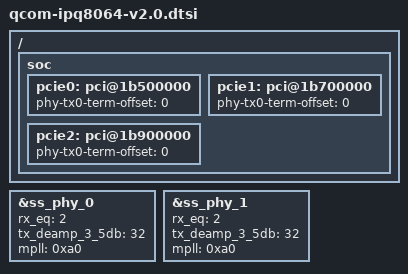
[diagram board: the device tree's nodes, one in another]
#include "qcom-ipq8064-v1.0.dtsi"

/ {
	soc: soc {

		pcie0: pci@1b500000 {
			phy-tx0-term-offset = <0>;
		};

		pcie1: pci@1b700000 {
			phy-tx0-term-offset = <0>;
		};

		pcie2: pci@1b900000 {
			phy-tx0-term-offset = <0>;
		};
	};
};

&ss_phy_0 {
	rx_eq = <2>;
	tx_deamp_3_5db = <32>;
	mpll = <0xa0>;
};

&ss_phy_1 {
	rx_eq = <2>;
	tx_deamp_3_5db = <32>;
	mpll = <0xa0>;
};
